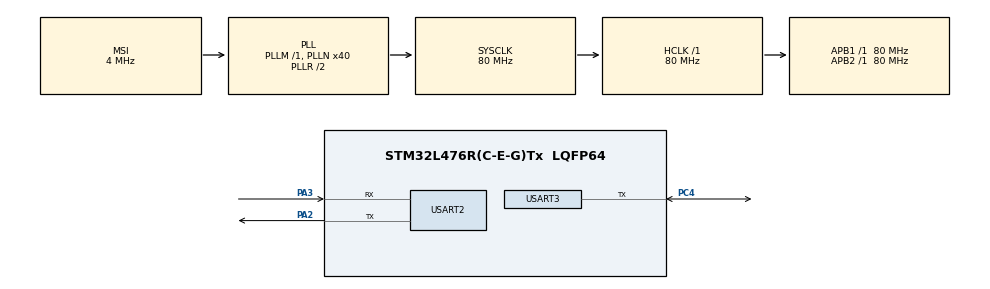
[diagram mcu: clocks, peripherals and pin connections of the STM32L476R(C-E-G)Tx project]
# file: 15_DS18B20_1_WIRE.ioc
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Mcu.Family=STM32L4
Mcu.Name=STM32L476R(C-E-G)Tx
Mcu.Package=LQFP64
NVIC.PriorityGroup=NVIC_PRIORITYGROUP_4
PA13\ (JTMS-SWDIO).Mode=Serial_Wire
PA13\ (JTMS-SWDIO).Signal=SYS_JTMS-SWDIO
PA14\ (JTCK-SWCLK).Mode=Serial_Wire
PA14\ (JTCK-SWCLK).Signal=SYS_JTCK-SWCLK
PA2.Mode=Asynchronous
PA2.Signal=USART2_TX
PA3.Mode=Asynchronous
PA3.Signal=USART2_RX
PC14-OSC32_IN\ (PC14).Mode=LSE-External-Oscillator
PC14-OSC32_IN\ (PC14).Signal=RCC_OSC32_IN
PC15-OSC32_OUT\ (PC15).Mode=LSE-External-Oscillator
PC15-OSC32_OUT\ (PC15).Signal=RCC_OSC32_OUT
PC4.GPIO_ModeDefaultPP=GPIO_MODE_AF_OD
PC4.Mode=Half_duplex(single_wire_mode)
PC4.Signal=USART3_TX
ProjectManager.HeapSize=0x200
ProjectManager.StackSize=0x400
ProjectManager.TargetToolchain=STM32CubeIDE
RCC.AHBFreq_Value=80000000
RCC.APB1Freq_Value=80000000
RCC.APB1TimFreq_Value=80000000
RCC.APB2Freq_Value=80000000
RCC.APB2TimFreq_Value=80000000
RCC.CortexFreq_Value=80000000
RCC.HCLKFreq_Value=80000000
RCC.HSE_VALUE=8000000
RCC.HSI_VALUE=16000000
RCC.MSI_VALUE=4000000
RCC.PLLN=40
RCC.SYSCLKFreq_VALUE=80000000
RCC.SYSCLKSource=RCC_SYSCLKSOURCE_PLLCLK
RCC.VCOOutputFreq_Value=160000000
TIM6.Prescaler=79
USART2.VirtualMode-Asynchronous=VM_ASYNC
USART3.BaudRate=9600
USART3.OverrunDisableParam=ADVFEATURE_OVERRUN_DISABLE
USART3.VirtualMode-Half_duplex(single_wire_mode)=VM_ASYNC
VP_TIM6_VS_ClockSourceINT.Mode=Enable_Timer
board=custom

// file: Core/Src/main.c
/* USER CODE BEGIN Header */
/**
  ******************************************************************************
  * @file           : main.c
  * @brief          : Main program body
  ******************************************************************************
  * @attention
  *
  * Copyright (c) 2024 STMicroelectronics.
  * All rights reserved.
  *
  * This software is licensed under terms that can be found in the LICENSE file
  * in the root directory of this software component.
  * If no LICENSE file comes with this software, it is provided AS-IS.
  *
  ******************************************************************************
  */
/* USER CODE END Header */
#include "main.h"
#include "tim.h"
#include "usart.h"
#include "gpio.h"

/* USER CODE BEGIN Includes */
#include <stdio.h>
#include "ds18b20.h"
/* USER CODE END Includes */

void SystemClock_Config(void);

/* USER CODE BEGIN 0 */

int __io_putchar(int ch)
{
  if (ch == '\n') {
    __io_putchar('\r');
  }

  HAL_UART_Transmit(&huart2, (uint8_t*)&ch, 1, HAL_MAX_DELAY);

  return 1;
}

/* USER CODE END 0 */

int main(void)
{

  /* MCU Configuration--------------------------------------------------------*/

  /* Reset of all peripherals, Initializes the Flash interface and the Systick. */
  HAL_Init();

  /* Configure the system clock */
  SystemClock_Config();

  /* Initialize all configured peripherals */
  MX_GPIO_Init();
  MX_TIM6_Init();
  MX_USART2_UART_Init();
  MX_USART3_UART_Init();
  /* USER CODE BEGIN 2 */

  if (ds18b20_init() != HAL_OK)
    Error_Handler();

  /*
  uint8_t ds1[DS18B20_ROM_CODE_SIZE];

  if (ds18b20_read_address(ds1) != HAL_OK)
    Error_Handler();
  */

  const uint8_t ds1[] = { 0x28, 0xc3, 0xd1, 0x11, 0x0, 0x0, 0x0, 0xfc };
  const uint8_t ds2[] = { 0x28, 0xa7, 0x02, 0x11, 0x0, 0x0, 0x0, 0xf3 };

  /* USER CODE END 2 */

  /* Infinite loop */
  /* USER CODE BEGIN WHILE */
  while (1)
  {
	  //ds18b20_start_measure(NULL);
	  ds18b20_start_measure(ds1);
	  ds18b20_start_measure(ds2);

	  HAL_Delay(750);

	  float temp = ds18b20_get_temp(ds1);
	  if (temp >= 80.0f)
	    printf("Sensor error...\n");
	  else
	    printf("T1 = %.1f*C\n", temp);

	  temp = ds18b20_get_temp(ds2);
	  if (temp >= 80.0f)
	    printf("Sensor error...\n");
	  else
	    printf("T2 = %.1f*C\n", temp);

    /* USER CODE END WHILE */

  }
}

void SystemClock_Config(void)
{
  RCC_OscInitTypeDef RCC_OscInitStruct = {0};
  RCC_ClkInitTypeDef RCC_ClkInitStruct = {0};

  /** Configure the main internal regulator output voltage
  */
  if (HAL_PWREx_ControlVoltageScaling(PWR_REGULATOR_VOLTAGE_SCALE1) != HAL_OK)
  {
    Error_Handler();
  }

  /** Configure LSE Drive Capability
  */
  HAL_PWR_EnableBkUpAccess();
  __HAL_RCC_LSEDRIVE_CONFIG(RCC_LSEDRIVE_LOW);

  /** Initializes the RCC Oscillators according to the specified parameters
  * in the RCC_OscInitTypeDef structure.
  */
  RCC_OscInitStruct.OscillatorType = RCC_OSCILLATORTYPE_LSE|RCC_OSCILLATORTYPE_MSI;
  RCC_OscInitStruct.LSEState = RCC_LSE_ON;
  RCC_OscInitStruct.MSIState = RCC_MSI_ON;
  RCC_OscInitStruct.MSICalibrationValue = 0;
  RCC_OscInitStruct.MSIClockRange = RCC_MSIRANGE_6;
  RCC_OscInitStruct.PLL.PLLState = RCC_PLL_ON;
  RCC_OscInitStruct.PLL.PLLSource = RCC_PLLSOURCE_MSI;
  RCC_OscInitStruct.PLL.PLLM = 1;
  RCC_OscInitStruct.PLL.PLLN = 40;
  RCC_OscInitStruct.PLL.PLLP = RCC_PLLP_DIV7;
  RCC_OscInitStruct.PLL.PLLQ = RCC_PLLQ_DIV2;
  RCC_OscInitStruct.PLL.PLLR = RCC_PLLR_DIV2;
  if (HAL_RCC_OscConfig(&RCC_OscInitStruct) != HAL_OK)
  {
    Error_Handler();
  }

  /** Initializes the CPU, AHB and APB buses clocks
  */
  RCC_ClkInitStruct.ClockType = RCC_CLOCKTYPE_HCLK|RCC_CLOCKTYPE_SYSCLK
                              |RCC_CLOCKTYPE_PCLK1|RCC_CLOCKTYPE_PCLK2;
  RCC_ClkInitStruct.SYSCLKSource = RCC_SYSCLKSOURCE_PLLCLK;
  RCC_ClkInitStruct.AHBCLKDivider = RCC_SYSCLK_DIV1;
  RCC_ClkInitStruct.APB1CLKDivider = RCC_HCLK_DIV1;
  RCC_ClkInitStruct.APB2CLKDivider = RCC_HCLK_DIV1;

  if (HAL_RCC_ClockConfig(&RCC_ClkInitStruct, FLASH_LATENCY_4) != HAL_OK)
  {
    Error_Handler();
  }

  /** Enable MSI Auto calibration
  */
  HAL_RCCEx_EnableMSIPLLMode();
}

void Error_Handler(void)
{
  __disable_irq();
  while (1)
  {
  }
}
